# STM32G071 register map
File version: 2.1
CPU: CM0 r0p1, little endian, MPU, no FPU, 4 interrupt priority bits
Registers are 32-bit, read-write, reset 0x0 unless marked. A register's access mark holds for its fields unless they carry their own. Offsets are from the block's base; [hi:lo] are bit positions; {n}, {i} and the like mark numbered series; 'fields as' and 'values as' point back to an identical list.

## COMP — COMP1
Base 0x40010200
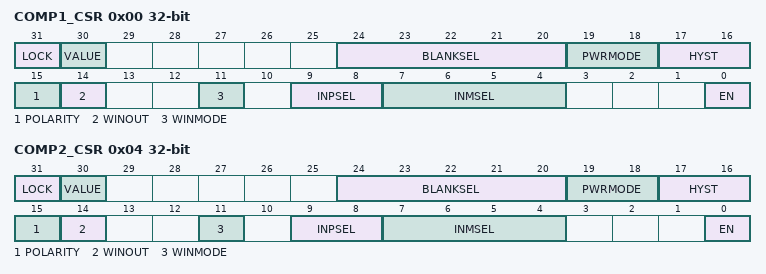
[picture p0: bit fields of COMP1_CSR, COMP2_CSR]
0x00 COMP1_CSR — Comparator 1 control and status register
  [31] LOCK — COMP2_CSR register lock
  [30] VALUE — Comparator 2 output status
  [24:20] BLANKSEL — Comparator 2 blanking source selector
  [19:18] PWRMODE — Comparator 2 power mode selector
  [17:16] HYST — Comparator 2 hysteresis selector
  [15] POLARITY — Comparator 2 polarity selector
  [14] WINOUT — Comparator 2 output selector
  [11] WINMODE — Comparator 2 non-inverting input selector for window mode
  [9:8] INPSEL — Comparator 2 signal selector for non-inverting input
  [7:4] INMSEL — Comparator 2 signal selector for inverting input INM
  [0] EN — COMP channel 1 enable bit
0x04 COMP2_CSR — Comparator 2 control and status register
  fields as COMP1_CSR

## TAMP — Tamper and backup registers
Base 0x4000B000
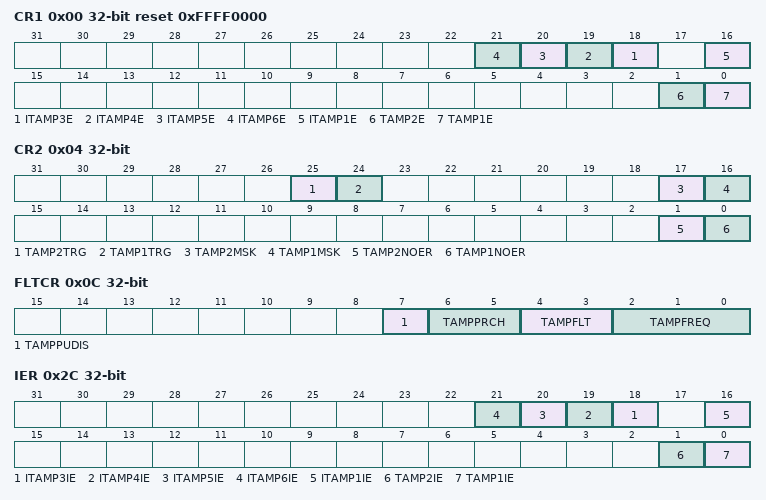
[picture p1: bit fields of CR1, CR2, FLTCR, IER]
0x00 CR1 reset 0xFFFF0000 — control register 1
  [n+15] ITAMP{n}E (n=3..6), [16] ITAMP1E, [1] TAMP2E, [0] TAMP1E
0x04 CR2 — control register 2
  [25] TAMP2TRG, [24] TAMP1TRG, [17] TAMP2MSK, [16] TAMP1MSK, [1] TAMP2NOER, [0] TAMP1NOER
0x0C FLTCR — TAMP filter control register
  [7] TAMPPUDIS, [6:5] TAMPPRCH, [4:3] TAMPFLT, [2:0] TAMPFREQ
0x2C IER — TAMP interrupt enable register
  [n+15] ITAMP{n}IE (n=3..6), [16] ITAMP1IE, [1] TAMP2IE, [0] TAMP1IE
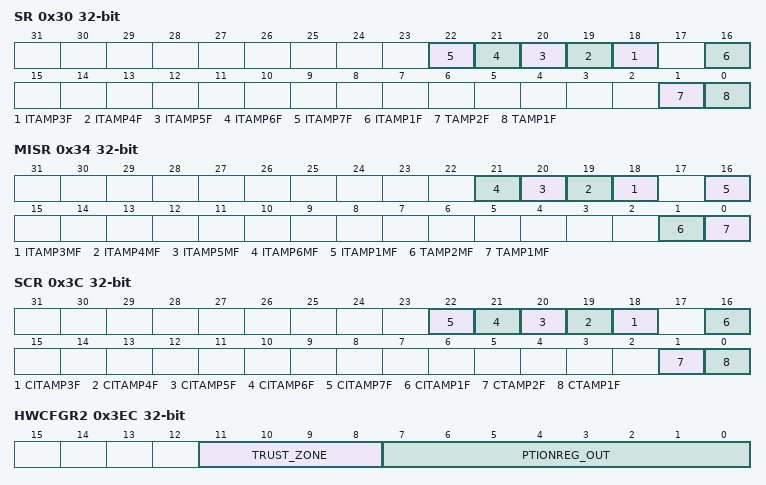
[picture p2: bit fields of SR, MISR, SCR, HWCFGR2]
0x30 SR ro — TAMP status register
  [n+15] ITAMP{n}F (n=3..7), [16] ITAMP1F, [1] TAMP2F, [0] TAMP1F
0x34 MISR ro — TAMP masked interrupt status register
  [n+15] ITAMP{n}MF (n=3..6), [16] ITAMP1MF, [1] TAMP2MF, [0] TAMP1MF
0x3C SCR wo — TAMP status clear register
  [n+15] CITAMP{n}F (n=3..7), [16] CITAMP1F, [1] CTAMP2F, [0] CTAMP1F
{0x100+4i} BKP{i}R (i=0..4) — TAMP backup register
  [31:0] BKP
0x3EC HWCFGR2 ro — TAMP hardware configuration register 2
  [11:8] TRUST_ZONE, [7:0] PTIONREG_OUT
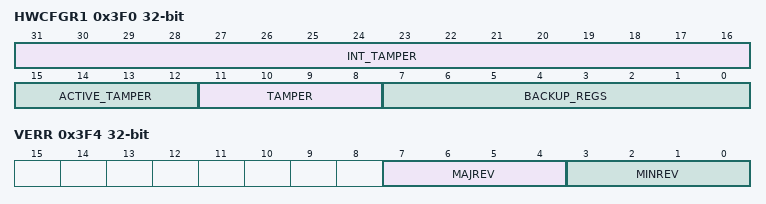
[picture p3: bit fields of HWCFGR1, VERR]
0x3F0 HWCFGR1 ro — TAMP hardware configuration register 1
  [31:16] INT_TAMPER, [15:12] ACTIVE_TAMPER, [11:8] TAMPER, [7:0] BACKUP_REGS
0x3F4 VERR ro — EXTI IP Version register
  [7:4] MAJREV — Major Revision number
  [3:0] MINREV — Minor Revision number
0x3F8 IPIDR ro — EXTI Identification register
  [31:0] IPID — IP Identification
0x3FC SIDR ro — EXTI Size ID register
  [31:0] SID — Size Identification

## UCPD1 — USB Power Delivery interface
Base 0x4000A000
Same registers: UCPD2 0x4000A400
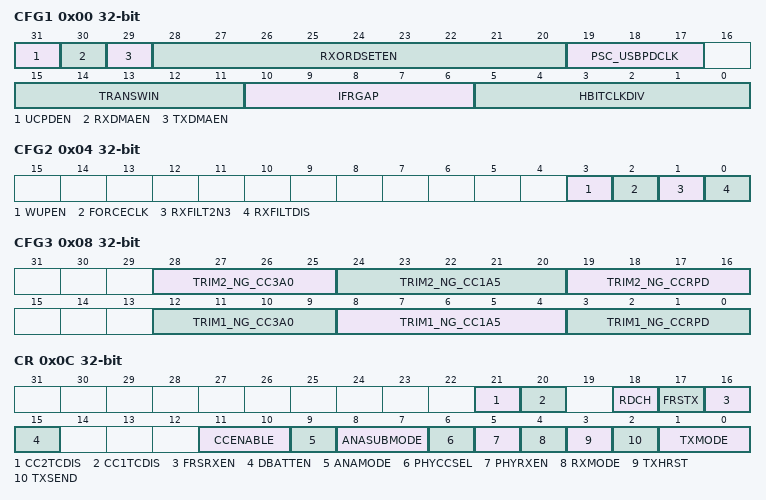
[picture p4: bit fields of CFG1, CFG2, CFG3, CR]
0x00 CFG1 — UCPD configuration register
  [31] UCPDEN, [30] RXDMAEN, [29] TXDMAEN, [28:20] RXORDSETEN, [19:17] PSC_USBPDCLK, [15:11] TRANSWIN, [10:6] IFRGAP, [5:0] HBITCLKDIV
0x04 CFG2 — UCPD configuration register 2
  [3] WUPEN, [2] FORCECLK, [1] RXFILT2N3, [0] RXFILTDIS
0x08 CFG3 — UCPD configuration register 3
  [28:25] TRIM2_NG_CC3A0, [24:20] TRIM2_NG_CC1A5, [19:16] TRIM2_NG_CCRPD, [12:9] TRIM1_NG_CC3A0, [8:4] TRIM1_NG_CC1A5, [3:0] TRIM1_NG_CCRPD
0x0C CR — UCPD control register
  [21] CC2TCDIS, [20] CC1TCDIS, [18] RDCH, [17] FRSTX, [16] FRSRXEN, [15] DBATTEN, [11:10] CCENABLE, [9] ANAMODE, [8:7] ANASUBMODE, [6] PHYCCSEL, [5] PHYRXEN, [4] RXMODE, [3] TXHRST, [2] TXSEND, [1:0] TXMODE
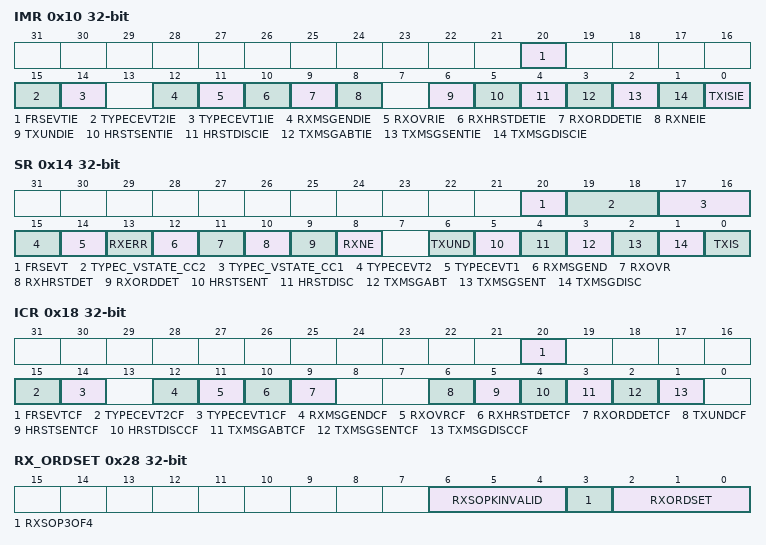
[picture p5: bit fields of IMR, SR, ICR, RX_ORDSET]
0x10 IMR — UCPD Interrupt Mask Register
  [20] FRSEVTIE, [15] TYPECEVT2IE, [14] TYPECEVT1IE, [12] RXMSGENDIE, [11] RXOVRIE, [10] RXHRSTDETIE, [9] RXORDDETIE, [8] RXNEIE, [6] TXUNDIE, [5] HRSTSENTIE, [4] HRSTDISCIE, [3] TXMSGABTIE, [2] TXMSGSENTIE, [1] TXMSGDISCIE, [0] TXISIE
0x14 SR ro — UCPD Status Register
  [20] FRSEVT, [19:18] TYPEC_VSTATE_CC2, [17:16] TYPEC_VSTATE_CC1, [15] TYPECEVT2, [14] TYPECEVT1, [13] RXERR, [12] RXMSGEND, [11] RXOVR, [10] RXHRSTDET, [9] RXORDDET, [8] RXNE, [6] TXUND, [5] HRSTSENT, [4] HRSTDISC, [3] TXMSGABT, [2] TXMSGSENT, [1] TXMSGDISC, [0] TXIS
0x18 ICR — UCPD Interrupt Clear Register
  [20] FRSEVTCF, [15] TYPECEVT2CF, [14] TYPECEVT1CF, [12] RXMSGENDCF, [11] RXOVRCF, [10] RXHRSTDETCF, [9] RXORDDETCF, [6] TXUNDCF, [5] HRSTSENTCF, [4] HRSTDISCCF, [3] TXMSGABTCF, [2] TXMSGSENTCF, [1] TXMSGDISCCF
0x1C TX_ORDSET — UCPD Tx Ordered Set Type Register
  [19:0] TXORDSET
0x20 TX_PAYSZ — UCPD Tx Paysize Register
  [9:0] TXPAYSZ
0x24 TXDR — UCPD Tx Data Register
  [7:0] TXDATA
0x28 RX_ORDSET ro — UCPD Rx Ordered Set Register
  [6:4] RXSOPKINVALID, [3] RXSOP3OF4, [2:0] RXORDSET
0x2C RX_PAYSZ — UCPD Rx Paysize Register
  [9:0] RXPAYSZ
0x30 RXDR ro — UCPD Receive Data Register
  [7:0] RXDATA
0x34 RX_ORDEXT1 — UCPD Rx Ordered Set Extension Register
  [19:0] RXSOPX1
0x38 RX_ORDEXT2 — UCPD Rx Ordered Set Extension Register
  [19:0] RXSOPX2
0x3F4 IPVER ro reset 0x10 — UCPD IP ID register
0x3F8 IPID ro reset 0x150021 — UCPD IP ID register
0x3FC MID ro reset 0xA3C5DD01 — UCPD IP ID register
  [31:0] IPID
